# MSPM0L222X register map
Vendor: Texas Instruments; File version: This preliminary header file does not have a version number - build date: 2024-04-29 20:57:13
CPU: CM0 r0p1, little endian, MPU, no FPU, 3 interrupt priority bits
Registers are 32-bit, read-write, reset 0x0 unless marked. A register's access mark holds for its fields unless they carry their own. Offsets are from the block's base; [hi:lo] are bit positions; {n}, {i} and the like mark numbered series.

## KEYSTORECTL — PERIPHERALREGION
Base 0x400AC000
0x1100 KEYSTORECTL_CFG reset 0x1 — Keystore configuration
  [3:0] NK256 — Number of 256 bit keys to be held in the key-store. Can not exceed the total number of slots present in the hardware / 2. For eg: if SYS_N_SLOTS = 4, then atmost 2 256-bit keys can be held in the key-store. Incorrect setting of this field will be reported via STATUS register
    0=ZERO (No 256-bit keys); 1=ONE (One 256-bit key); 2=TWO (Two 256-bit keys); 3=THREE (Three 256-bit keys); 4=FOUR (Four 256-bit keys)
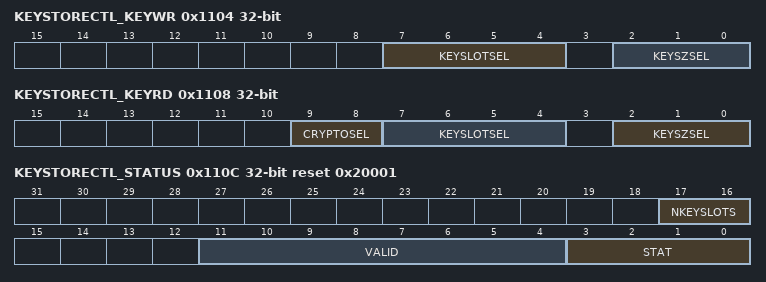
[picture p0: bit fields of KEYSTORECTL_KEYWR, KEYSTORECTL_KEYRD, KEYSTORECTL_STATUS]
0x1104 KEYSTORECTL_KEYWR — Key write configuration
  [7:4] KEYSLOTSEL — Select the key slot to write the key into. NOTE: SW needs to ensure that it is writing to the correct slots. The slot numbering is from 0 through SYS_N_SLOTS-1. Each slot is a 128-bit slot. Therefore, when writing a 256-bit key, two slots will need to budgeted.
    {v}=SLOT{v} (v=0..7)
  [2:0] KEYSZSEL — Key size selection. Selection of 128 or 256 bit keys
    0=K256 (256 bit key); 1=K128 (128 bit key)
0x1108 KEYSTORECTL_KEYRD — Key read configuration
  [9:8] CRYPTOSEL — Crypto engine selector
    0=AES (Transfer key to AES)
  [7:4] KEYSLOTSEL — Select the key slot to read the key from. NOTE: SW needs to ensure that it is reading from the correct slots. The slot numbering is from 0 through SYS_N_SLOTS-1. Each slot is a 128-bit slot. Therefore, when reading a 256-bit key, two adjacent slots will be read.
  [2:0] KEYSZSEL — Key size selection. Selection of 128 or 256 bit keys
    0=K256 (256 bit key); 1=K128 (128 bit key)
0x110C KEYSTORECTL_STATUS ro reset 0x20001 — Status
  [17:16] NKEYSLOTS — Size of keystorage: Number of 128-bit key slots
    0=TWO (Two slots); 1=THREE (Three slots); 2=FOUR (Four slots)
  [11:4] VALID — Bitvector of valid bits to indicate which slots have been configured
  [3:0] STAT — Status information
    0=VALID (Valid configuration); 1=NO_CFG (Key-store has not been configured. NK256 has not been set.); 2=INVALID_NK256 (Invalid value for NK256 field in CFG.); 3=BUSY_RECEIVE (Busy receiving a key deposit); 4=BUSY_TRANSMIT (Busy transmitting a key to a crypto engine); 5=INVALID_KEYSLOTSELW (Invalid keyslot selection for writing); 6=INVALID_KEYSLOTSELR (Invalid keyslot selection for reading)
0x1110 KEYSTORECTL_KEYIN wo — Input key

## IOMUX — PERIPHERALREGION
Base 0x40428000
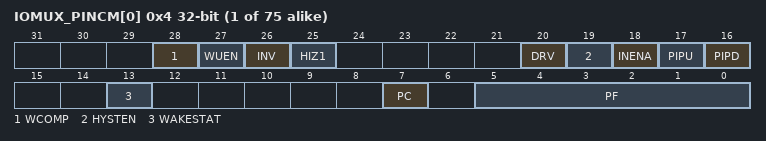
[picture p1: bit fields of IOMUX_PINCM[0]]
{0x4+4i} IOMUX_PINCM[{i}] (i=0..74) — Pin Control Management Register in SECCFG region
  [28] WCOMP — Wakeup Compare Value bit
    0=MATCH0 (Wakeup on a match of 0); 1=MATCH1 (Wakeup on a match of 1)
  [27] WUEN — Wakeup Enable bit
    0=DISABLE (wakeup is disabled.); 1=ENABLE (wakeup is enabled)
  [26] INV — Data inversion selection
    0=DISABLE (Data inversion is disabled.); 1=ENABLE (Data inversion is enabled)
  [25] HIZ1 — High output value will tri-state the output when this bit is enabled
    0=DISABLE (open-drain is disabled.); 1=ENABLE (open-drain is enabled.)
  [20] DRV — Drive strength control selection, for HS IOCELL only
    0=DRVVAL0 (Drive setting of 0 selected); 1=DRVVAL1 (Drive setting of 1 selected)
  [19] HYSTEN — Hystersis Enable Control Selection
    0=DISABLE (hysteresis is disabled.); 1=ENABLE (hysteresis is enabled)
  [18] INENA — Input Enable Control Selection
    0=DISABLE (Input enable is disabled.); 1=ENABLE (Input enable is enabled.)
  [17] PIPU — Pull Up control selection
    0=DISABLE (Pull up is disabled.); 1=ENABLE (Pull up is enabled)
  [16] PIPD — Pull Down control selection
    0=DISABLE (Pull down is disabled.); 1=ENABLE (Pull down is enabled)
  [13] WAKESTAT ro — This has the IOPAD WAKEUP signal as status bit.
    0=DISABLE (wakeup source is NOT from this IOCELL); 1=ENABLE (wakeup source is from this IOCELL)
  [7] PC — Peripheral is Connected
    0=UNCONNECTED (The output of the peripheral (and its output enable) will not propagate to the IOCELL); 1=CONNECTED (The output latch of the dataflow will be transparent)
  [5:0] PF — P channel Function selection bits
